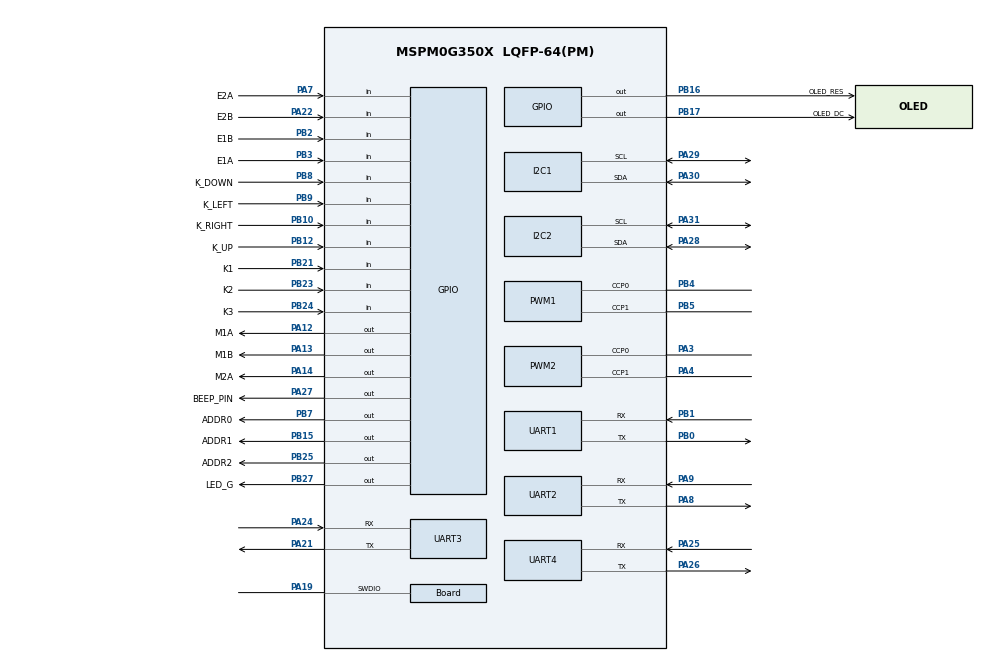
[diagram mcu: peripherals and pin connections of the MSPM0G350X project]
/**
 * @cliArgs --device "MSPM0G350X" --part "Default" --package "LQFP-64(PM)" --product "mspm0_sdk@2.10.00.04"
 * @versions {"tool":"1.27.1+4634"}
 */

/**
 * Import the modules used in this configuration.
 */
const ADC12         = scripting.addModule("/ti/driverlib/ADC12", {}, false);
const ADC121        = ADC12.addInstance();
const Board         = scripting.addModule("/ti/driverlib/Board");
const GPIO          = scripting.addModule("/ti/driverlib/GPIO", {}, false);
const GPIO1         = GPIO.addInstance();
const GPIO2         = GPIO.addInstance();
const GPIO3         = GPIO.addInstance();
const GPIO4         = GPIO.addInstance();
const GPIO5         = GPIO.addInstance();
const GPIO6         = GPIO.addInstance();
const GPIO7         = GPIO.addInstance();
const GPIO8         = GPIO.addInstance();
const GPIO9         = GPIO.addInstance();
const I2C           = scripting.addModule("/ti/driverlib/I2C", {}, false);
const I2C1          = I2C.addInstance();
const I2C2          = I2C.addInstance();
const PWM           = scripting.addModule("/ti/driverlib/PWM", {}, false);
const PWM1          = PWM.addInstance();
const PWM2          = PWM.addInstance();
const SPI           = scripting.addModule("/ti/driverlib/SPI", {}, false);
const SPI1          = SPI.addInstance();
const UART          = scripting.addModule("/ti/driverlib/UART", {}, false);
const UART1         = UART.addInstance();
const UART2         = UART.addInstance();
const UART3         = UART.addInstance();
const UART4         = UART.addInstance();
const ProjectConfig = scripting.addModule("/ti/project_config/ProjectConfig");

/**
 * Write custom configuration values to the imported modules.
 */
ADC121.$name               = "ADC12_0";
ADC121.enableDMA           = false;
ADC121.sampClkSrc          = "DL_ADC12_CLOCK_ULPCLK";
ADC121.enabledInterrupts   = ["DL_ADC12_INTERRUPT_MEM0_RESULT_LOADED"];
ADC121.adcMem1chansel      = "DL_ADC12_INPUT_CHAN_1";
ADC121.sampClkDiv          = "DL_ADC12_CLOCK_DIVIDE_8";
ADC121.adcMem2chansel      = "DL_ADC12_INPUT_CHAN_5";
ADC121.adcMem0chansel      = "DL_ADC12_INPUT_CHAN_5";
ADC121.sampleTime0         = "125us";
ADC121.peripheral.$assign  = "ADC1";
ADC121.adcPin5Config.$name = "ti_driverlib_gpio_GPIOPinGeneric14";

Board.peripheral.swdioPin.$assign = "PA19";

GPIO1.port                    = "PORTA";
GPIO1.portSegment             = "Lower";
GPIO1.$name                   = "LED";
GPIO1.associatedPins[0].$name = "LED0_PIN";

GPIO2.$name                                       = "LED_RGB";
GPIO2.port                                        = "PORTB";
GPIO2.portSegment                                 = "Upper";
GPIO2.associatedPins.create(3);
GPIO2.associatedPins[0].$name                     = "LED_R";
GPIO2.associatedPins[0].pin.$assignAllowConflicts = "PB26";
GPIO2.associatedPins[1].$name                     = "LED_G";
GPIO2.associatedPins[1].pin.$assign               = "PB27";
GPIO2.associatedPins[2].$name                     = "LED_B";
GPIO2.associatedPins[2].pin.$assignAllowConflicts = "PB22";

GPIO3.$name                         = "BEEP";
GPIO3.port                          = "PORTA";
GPIO3.portSegment                   = "Upper";
GPIO3.associatedPins[0].$name       = "BEEP_PIN";
GPIO3.associatedPins[0].pin.$assign = "PA27";

GPIO4.$name                              = "KEY3";
GPIO4.port                               = "PORTB";
GPIO4.associatedPins.create(3);
GPIO4.associatedPins[0].$name            = "K1";
GPIO4.associatedPins[0].direction        = "INPUT";
GPIO4.associatedPins[0].ioStructure      = "SD";
GPIO4.associatedPins[0].internalResistor = "PULL_UP";
GPIO4.associatedPins[0].pin.$assign      = "PB21";
GPIO4.associatedPins[1].$name            = "K2";
GPIO4.associatedPins[1].direction        = "INPUT";
GPIO4.associatedPins[1].ioStructure      = "SD";
GPIO4.associatedPins[1].internalResistor = "PULL_UP";
GPIO4.associatedPins[1].pin.$assign      = "PB23";
GPIO4.associatedPins[2].$name            = "K3";
GPIO4.associatedPins[2].direction        = "INPUT";
GPIO4.associatedPins[2].ioStructure      = "SD";
GPIO4.associatedPins[2].internalResistor = "PULL_UP";
GPIO4.associatedPins[2].pin.$assign      = "PB24";

GPIO5.$name                                       = "KEY5";
GPIO5.associatedPins.create(5);
GPIO5.associatedPins[0].direction                 = "INPUT";
GPIO5.associatedPins[0].ioStructure               = "SD";
GPIO5.associatedPins[0].$name                     = "K_UP";
GPIO5.associatedPins[0].pin.$assign               = "PB12";
GPIO5.associatedPins[1].$name                     = "K_DOWN";
GPIO5.associatedPins[1].direction                 = "INPUT";
GPIO5.associatedPins[1].ioStructure               = "SD";
GPIO5.associatedPins[1].pin.$assign               = "PB8";
GPIO5.associatedPins[2].$name                     = "K_LEFT";
GPIO5.associatedPins[2].direction                 = "INPUT";
GPIO5.associatedPins[2].ioStructure               = "SD";
GPIO5.associatedPins[2].pin.$assign               = "PB9";
GPIO5.associatedPins[3].$name                     = "K_RIGHT";
GPIO5.associatedPins[3].direction                 = "INPUT";
GPIO5.associatedPins[3].ioStructure               = "SD";
GPIO5.associatedPins[3].pin.$assign               = "PB10";
GPIO5.associatedPins[4].$name                     = "K_MAIN";
GPIO5.associatedPins[4].direction                 = "INPUT";
GPIO5.associatedPins[4].ioStructure               = "SD";
GPIO5.associatedPins[4].pin.$assignAllowConflicts = "PB11";

GPIO6.$name                         = "ENCODER_PIN";
GPIO6.associatedPins.create(4);
GPIO6.associatedPins[0].$name       = "E1A";
GPIO6.associatedPins[0].direction   = "INPUT";
GPIO6.associatedPins[0].interruptEn = true;
GPIO6.associatedPins[0].polarity    = "RISE_FALL";
GPIO6.associatedPins[0].ioStructure = "SD";
GPIO6.associatedPins[0].pin.$assign = "PB3";
GPIO6.associatedPins[1].$name       = "E1B";
GPIO6.associatedPins[1].direction   = "INPUT";
GPIO6.associatedPins[1].interruptEn = true;
GPIO6.associatedPins[1].polarity    = "RISE_FALL";
GPIO6.associatedPins[1].ioStructure = "SD";
GPIO6.associatedPins[1].pin.$assign = "PB2";
GPIO6.associatedPins[2].$name       = "E2A";
GPIO6.associatedPins[2].direction   = "INPUT";
GPIO6.associatedPins[2].interruptEn = true;
GPIO6.associatedPins[2].polarity    = "RISE_FALL";
GPIO6.associatedPins[2].ioStructure = "SD";
GPIO6.associatedPins[2].pin.$assign = "PA7";
GPIO6.associatedPins[3].$name       = "E2B";
GPIO6.associatedPins[3].direction   = "INPUT";
GPIO6.associatedPins[3].interruptEn = true;
GPIO6.associatedPins[3].polarity    = "RISE_FALL";
GPIO6.associatedPins[3].ioStructure = "SD";
GPIO6.associatedPins[3].pin.$assign = "PA22";

GPIO7.$name                                       = "MOTOR_PIN";
GPIO7.associatedPins.create(4);
GPIO7.associatedPins[0].$name                     = "M1A";
GPIO7.associatedPins[0].pin.$assign               = "PA12";
GPIO7.associatedPins[1].$name                     = "M1B";
GPIO7.associatedPins[1].pin.$assign               = "PA13";
GPIO7.associatedPins[2].$name                     = "M2A";
GPIO7.associatedPins[2].pin.$assign               = "PA14";
GPIO7.associatedPins[3].$name                     = "M2B";
GPIO7.associatedPins[3].pin.$assignAllowConflicts = "PA16";

GPIO8.$name                         = "GW_ADDR_PIN";
GPIO8.associatedPins.create(3);
GPIO8.associatedPins[0].$name       = "ADDR2";
GPIO8.associatedPins[0].pin.$assign = "PB25";
GPIO8.associatedPins[1].$name       = "ADDR1";
GPIO8.associatedPins[1].pin.$assign = "PB15";
GPIO8.associatedPins[2].$name       = "ADDR0";
GPIO8.associatedPins[2].pin.$assign = "PB7";

GPIO9.$name                         = "OLED_CTRL";
GPIO9.associatedPins.create(2);
GPIO9.associatedPins[0].$name       = "OLED_RES";
GPIO9.associatedPins[0].pin.$assign = "PB16";
GPIO9.associatedPins[1].$name       = "OLED_DC";
GPIO9.associatedPins[1].pin.$assign = "PB17";

I2C1.$name                             = "MPU6050_I2C";
I2C1.basicEnableController             = true;
I2C1.advDigitalGlitchFilter            = "CLOCKS_1";
I2C1.advControllerRXFIFOTRIG           = "BYTES_8";
I2C1.advControllerTXFIFOTRIG           = "BYTES_7";
I2C1.enableDMAEvent1                   = false;
I2C1.enableDMAEvent2                   = false;
I2C1.basicControllerStandardBusSpeed   = "Fast";
I2C1.intController                     = ["ARBITRATION_LOST","EVENT1_DMA_DONE","EVENT2_DMA_DONE","NACK","RXFIFO_FULL","RXFIFO_TRIGGER","RX_DONE","START","STOP","TXFIFO_EMPTY","TXFIFO_TRIGGER","TX_DONE"];
I2C1.peripheral.$assign                = "I2C1";
I2C1.peripheral.sdaPin.$assign         = "PA30";
I2C1.peripheral.sclPin.$assign         = "PA29";
I2C1.sdaPinConfig.hideOutputInversion  = scripting.forceWrite(false);
I2C1.sdaPinConfig.onlyInternalResistor = scripting.forceWrite(false);
I2C1.sdaPinConfig.passedPeripheralType = scripting.forceWrite("Digital");
I2C1.sdaPinConfig.$name                = "ti_driverlib_gpio_GPIOPinGeneric8";
I2C1.sclPinConfig.hideOutputInversion  = scripting.forceWrite(false);
I2C1.sclPinConfig.onlyInternalResistor = scripting.forceWrite(false);
I2C1.sclPinConfig.passedPeripheralType = scripting.forceWrite("Digital");
I2C1.sclPinConfig.$name                = "ti_driverlib_gpio_GPIOPinGeneric9";

I2C2.$name                             = "OLED_I2C";
I2C2.basicEnableController             = true;
I2C2.basicControllerStandardBusSpeed   = "Fast";
I2C2.basicControllerBusSpeed           = 400000;
I2C2.basicEnableTarget                 = true;
I2C2.advDigitalGlitchFilter            = "CLOCKS_1";
I2C2.enableDMAEvent1                   = false;
I2C2.enableDMAEvent2                   = false;
I2C2.basicTargetSecAddressEnable       = false;
I2C2.basicTargetOwnAddressEnable       = false;
I2C2.intController                     = ["ARBITRATION_LOST","EVENT1_DMA_DONE","EVENT2_DMA_DONE","NACK","RXFIFO_FULL","RXFIFO_TRIGGER","RX_DONE","START","STOP","TXFIFO_EMPTY","TXFIFO_TRIGGER","TX_DONE"];
I2C2.peripheral.$assign                = "I2C0";
I2C2.peripheral.sdaPin.$assign         = "PA28";
I2C2.peripheral.sclPin.$assign         = "PA31";
I2C2.sdaPinConfig.$name                = "ti_driverlib_gpio_GPIOPinGeneric19";
I2C2.sdaPinConfig.hideOutputInversion  = scripting.forceWrite(false);
I2C2.sdaPinConfig.onlyInternalResistor = scripting.forceWrite(false);
I2C2.sdaPinConfig.passedPeripheralType = scripting.forceWrite("Digital");
I2C2.sclPinConfig.$name                = "ti_driverlib_gpio_GPIOPinGeneric20";
I2C2.sclPinConfig.hideOutputInversion  = scripting.forceWrite(false);
I2C2.sclPinConfig.onlyInternalResistor = scripting.forceWrite(false);
I2C2.sclPinConfig.passedPeripheralType = scripting.forceWrite("Digital");

PWM1.$name                              = "WHEEL_PWM";
PWM1.dutyArgs                           = "[50,0,0,0]";
PWM1.timerStartTimer                    = true;
PWM1.pwmMode                            = "EDGE_ALIGN_UP";
PWM1.clockPrescale                      = 8;
PWM1.peripheral.$assign                 = "TIMA1";
PWM1.peripheral.ccp0Pin.$assign         = "PB4";
PWM1.peripheral.ccp1Pin.$assign         = "PB5";
PWM1.PWM_CHANNEL_0.$name                = "ti_driverlib_pwm_PWMTimerCC0";
PWM1.PWM_CHANNEL_0.dutyCycle            = 0;
PWM1.PWM_CHANNEL_1.$name                = "ti_driverlib_pwm_PWMTimerCC1";
PWM1.ccp0PinConfig.direction            = scripting.forceWrite("OUTPUT");
PWM1.ccp0PinConfig.hideOutputInversion  = scripting.forceWrite(false);
PWM1.ccp0PinConfig.onlyInternalResistor = scripting.forceWrite(false);
PWM1.ccp0PinConfig.passedPeripheralType = scripting.forceWrite("Digital");
PWM1.ccp0PinConfig.$name                = "ti_driverlib_gpio_GPIOPinGeneric10";
PWM1.ccp1PinConfig.direction            = scripting.forceWrite("OUTPUT");
PWM1.ccp1PinConfig.hideOutputInversion  = scripting.forceWrite(false);
PWM1.ccp1PinConfig.onlyInternalResistor = scripting.forceWrite(false);
PWM1.ccp1PinConfig.passedPeripheralType = scripting.forceWrite("Digital");
PWM1.ccp1PinConfig.$name                = "ti_driverlib_gpio_GPIOPinGeneric11";

PWM2.$name                              = "PWM_0";
PWM2.clockPrescale                      = 32;
PWM2.timerCount                         = 20000;
PWM2.pwmMode                            = "EDGE_ALIGN_UP";
PWM2.peripheral.$assign                 = "TIMG7";
PWM2.peripheral.ccp0Pin.$assign         = "PA3";
PWM2.peripheral.ccp1Pin.$assign         = "PA4";
PWM2.PWM_CHANNEL_0.$name                = "ti_driverlib_pwm_PWMTimerCC2";
PWM2.PWM_CHANNEL_1.$name                = "ti_driverlib_pwm_PWMTimerCC3";
PWM2.ccp0PinConfig.direction            = scripting.forceWrite("OUTPUT");
PWM2.ccp0PinConfig.hideOutputInversion  = scripting.forceWrite(false);
PWM2.ccp0PinConfig.onlyInternalResistor = scripting.forceWrite(false);
PWM2.ccp0PinConfig.passedPeripheralType = scripting.forceWrite("Digital");
PWM2.ccp0PinConfig.$name                = "ti_driverlib_gpio_GPIOPinGeneric12";
PWM2.ccp1PinConfig.direction            = scripting.forceWrite("OUTPUT");
PWM2.ccp1PinConfig.hideOutputInversion  = scripting.forceWrite(false);
PWM2.ccp1PinConfig.onlyInternalResistor = scripting.forceWrite(false);
PWM2.ccp1PinConfig.passedPeripheralType = scripting.forceWrite("Digital");
PWM2.ccp1PinConfig.$name                = "ti_driverlib_gpio_GPIOPinGeneric13";

SPI1.$name                              = "OLED_SPI";
SPI1.peripheral.$assign                 = "SPI1";
SPI1.sclkPinConfig.direction            = scripting.forceWrite("OUTPUT");
SPI1.sclkPinConfig.onlyInternalResistor = scripting.forceWrite(false);
SPI1.sclkPinConfig.passedPeripheralType = scripting.forceWrite("Digital");
SPI1.sclkPinConfig.$name                = "ti_driverlib_gpio_GPIOPinGeneric15";
SPI1.mosiPinConfig.direction            = scripting.forceWrite("OUTPUT");
SPI1.mosiPinConfig.hideOutputInversion  = scripting.forceWrite(false);
SPI1.mosiPinConfig.onlyInternalResistor = scripting.forceWrite(false);
SPI1.mosiPinConfig.passedPeripheralType = scripting.forceWrite("Digital");
SPI1.mosiPinConfig.$name                = "ti_driverlib_gpio_GPIOPinGeneric16";
SPI1.misoPinConfig.onlyInternalResistor = scripting.forceWrite(false);
SPI1.misoPinConfig.passedPeripheralType = scripting.forceWrite("Digital");
SPI1.misoPinConfig.$name                = "ti_driverlib_gpio_GPIOPinGeneric17";
SPI1.cs0PinConfig.direction             = scripting.forceWrite("OUTPUT");
SPI1.cs0PinConfig.hideOutputInversion   = scripting.forceWrite(false);
SPI1.cs0PinConfig.onlyInternalResistor  = scripting.forceWrite(false);
SPI1.cs0PinConfig.passedPeripheralType  = scripting.forceWrite("Digital");
SPI1.cs0PinConfig.$name                 = "ti_driverlib_gpio_GPIOPinGeneric18";

const SYSCTL = scripting.addModule("/ti/driverlib/SYSCTL", {}, false);

UART1.$name                    = "UART_0";
UART1.targetBaudRate           = 115200;
UART1.enableFIFO               = true;
UART1.rxTimeoutValue           = 4;
UART1.enabledInterrupts        = ["BREAK_ERROR","CTS_DONE","DMA_DONE_RX","DMA_DONE_TX","EOT_DONE","FRAMING_ERROR","NOISE_ERROR","OVERRUN_ERROR","PARITY_ERROR","RX","RXD_NEG_EDGE","RXD_POS_EDGE","RX_TIMEOUT_ERROR","TX"];
UART1.enableInternalLoopback   = true;
UART1.peripheral.$assign       = "UART0";
UART1.peripheral.rxPin.$assign = "PB1";
UART1.peripheral.txPin.$assign = "PB0";
UART1.txPinConfig.$name        = "ti_driverlib_gpio_GPIOPinGeneric0";
UART1.rxPinConfig.$name        = "ti_driverlib_gpio_GPIOPinGeneric1";

UART2.$name                    = "UART_1";
UART2.targetBaudRate           = 115200;
UART2.enableFIFO               = true;
UART2.rxTimeoutValue           = 4;
UART2.enabledInterrupts        = ["BREAK_ERROR","CTS_DONE","DMA_DONE_RX","DMA_DONE_TX","EOT_DONE","FRAMING_ERROR","NOISE_ERROR","OVERRUN_ERROR","PARITY_ERROR","RX","RXD_NEG_EDGE","RXD_POS_EDGE","RX_TIMEOUT_ERROR","TX"];
UART2.enableInternalLoopback   = true;
UART2.peripheral.$assign       = "UART1";
UART2.peripheral.rxPin.$assign = "PA9";
UART2.peripheral.txPin.$assign = "PA8";
UART2.txPinConfig.$name        = "ti_driverlib_gpio_GPIOPinGeneric2";
UART2.rxPinConfig.$name        = "ti_driverlib_gpio_GPIOPinGeneric3";

UART3.$name                    = "UART_2";
UART3.targetBaudRate           = 115200;
UART3.enableFIFO               = true;
UART3.rxTimeoutValue           = 4;
UART3.enabledInterrupts        = ["BREAK_ERROR","CTS_DONE","DMA_DONE_RX","DMA_DONE_TX","EOT_DONE","FRAMING_ERROR","NOISE_ERROR","OVERRUN_ERROR","PARITY_ERROR","RX","RXD_NEG_EDGE","RXD_POS_EDGE","RX_TIMEOUT_ERROR","TX"];
UART3.enableInternalLoopback   = true;
UART3.peripheral.$assign       = "UART2";
UART3.peripheral.rxPin.$assign = "PA24";
UART3.peripheral.txPin.$assign = "PA21";
UART3.txPinConfig.$name        = "ti_driverlib_gpio_GPIOPinGeneric4";
UART3.rxPinConfig.$name        = "ti_driverlib_gpio_GPIOPinGeneric5";

UART4.$name                    = "UART_3";
UART4.targetBaudRate           = 115200;
UART4.enableFIFO               = true;
UART4.rxTimeoutValue           = 4;
UART4.enabledInterrupts        = ["BREAK_ERROR","CTS_DONE","DMA_DONE_RX","DMA_DONE_TX","EOT_DONE","FRAMING_ERROR","NOISE_ERROR","OVERRUN_ERROR","PARITY_ERROR","RX","RXD_NEG_EDGE","RXD_POS_EDGE","RX_TIMEOUT_ERROR","TX"];
UART4.enableInternalLoopback   = true;
UART4.peripheral.$assign       = "UART3";
UART4.peripheral.rxPin.$assign = "PA25";
UART4.peripheral.txPin.$assign = "PA26";
UART4.txPinConfig.$name        = "ti_driverlib_gpio_GPIOPinGeneric6";
UART4.rxPinConfig.$name        = "ti_driverlib_gpio_GPIOPinGeneric7";

ProjectConfig.genLibDrivers = true;

/**
 * Pinmux solution for unlocked pins/peripherals. This ensures that minor changes to the automatic solver in a future
 * version of the tool will not impact the pinmux you originally saw.  These lines can be completely deleted in order to
 * re-solve from scratch.
 */
ADC121.peripheral.adcPin5.$suggestSolution   = "PB18";
Board.peripheral.$suggestSolution            = "DEBUGSS";
Board.peripheral.swclkPin.$suggestSolution   = "PA20";
GPIO1.associatedPins[0].pin.$suggestSolution = "PA15";
SPI1.peripheral.sclkPin.$suggestSolution     = "PA17";
SPI1.peripheral.mosiPin.$suggestSolution     = "PA18";
SPI1.peripheral.misoPin.$suggestSolution     = "PB14";
SPI1.peripheral.cs0Pin.$suggestSolution      = "PA2";
SYSCTL.peripheral.$suggestSolution           = "SYSCTL";
